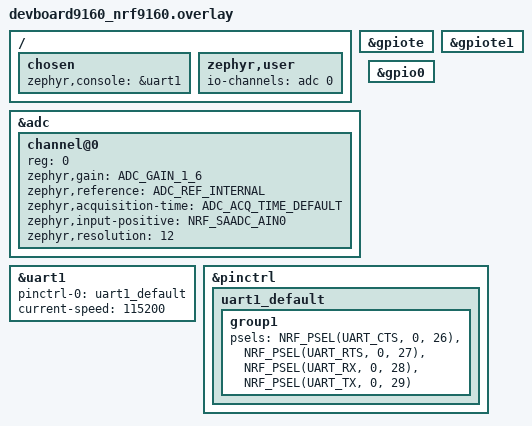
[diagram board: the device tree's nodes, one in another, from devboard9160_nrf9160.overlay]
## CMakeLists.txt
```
# SPDX-License-Identifier: Apache-2.0

cmake_minimum_required(VERSION 3.20.0)

find_package(Zephyr REQUIRED HINTS $ENV{ZEPHYR_BASE})
project(adc_simple)

target_sources(app PRIVATE src/main.c)
```

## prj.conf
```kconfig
CONFIG_GPIO=y

##enable the console
CONFIG_CONSOLE=y
CONFIG_UART_CONSOLE=y
CONFIG_SERIAL=y


#enable the logs
CONFIG_LOG=y
CONFIG_LOG_INFO_COLOR_GREEN=y
CONFIG_LOG_DBG_COLOR_BLUE=y

#enable ADC module
CONFIG_ADC=y
```

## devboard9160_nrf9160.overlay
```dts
/ {
	chosen {
		zephyr,console = &uart1;
	};

	zephyr,user {
		io-channels = <&adc 0>;
	};
};

&gpiote {
	status = "okay";
};

&gpiote1 {
	status = "okay";
};

&adc {
	#address-cells = <1>;
	#size-cells = <0>;
	status = "okay";
	channel@0 {
		reg = <0>;
		zephyr,gain = "ADC_GAIN_1_6";
		zephyr,reference = "ADC_REF_INTERNAL";
        zephyr,acquisition-time = <ADC_ACQ_TIME_DEFAULT>;
        zephyr,input-positive = <NRF_SAADC_AIN0>;
		zephyr,resolution = <12>;
	};
};

&gpio0 {
	status = "okay";
};

&uart1 {
	status = "okay";
	pinctrl-0 = <&uart1_default>;
	pinctrl-names = "default";
	current-speed = <115200>;
};

&pinctrl {
	uart1_default: uart1_default {
		group1 {
			psels = <NRF_PSEL(UART_CTS, 0, 26)>,
					<NRF_PSEL(UART_RTS, 0, 27)>,
					<NRF_PSEL(UART_RX, 0, 28)>,
					<NRF_PSEL(UART_TX, 0, 29)>;
		};
	};
};
```

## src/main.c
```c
/**
 * @file main.c
 * @author Ankit Bansal (iotdevelope@gmail.com)
 * @brief 
 * @version 0.1
 * @date 2025-01-24
 * 
 * @copyright Copyright (c) 2025
 * 
 */

/******************************************************************************
 * INCLUDES
 ******************************************************************************/
#include <stdio.h>
#include <zephyr/devicetree.h>
#include <zephyr/logging/log.h>
#include <zephyr/drivers/adc.h>

/******************************************************************************
 * EXTERN VARIABLES
 ******************************************************************************/

/******************************************************************************
 * PRIVATE MACROS AND DEFINES
 ******************************************************************************/
LOG_MODULE_REGISTER(main);
/******************************************************************************
 * PRIVATE TYPEDEFS
 ******************************************************************************/

/******************************************************************************
 * STATIC VARIABLES
 ******************************************************************************/
static const struct adc_dt_spec adc_channel = ADC_DT_SPEC_GET(DT_PATH(zephyr_user));

/******************************************************************************
 * GLOBAL VARIABLES
 ******************************************************************************/

/******************************************************************************
 * STATIC FUNCTION PROTOTYPES
 ******************************************************************************/

/******************************************************************************
 * STATIC FUNCTIONS
 ******************************************************************************/

/******************************************************************************
 * GLOBAL FUNCTIONS
 ******************************************************************************/


/******************************************************************************
* Function Prototypes
*******************************************************************************/

/******************************************************************************
* Function Definitions
*******************************************************************************/

int main()
{
    int err;
    if (!adc_is_ready_dt(&adc_channel))
    {
        LOG_ERR("ADC controller devivce %s not ready", adc_channel.dev->name);
        return 0;
    }

    err = adc_channel_setup_dt(&adc_channel);
    if( err < 0 )
    {
        LOG_ERR("Could not setup channel #%d (%d)", 0, err);
        return 0;
    }

    int16_t buf;
    struct adc_sequence sequence = {
        .buffer = &buf,
        .buffer_size = sizeof(buf),
    };

    err = adc_sequence_init_dt(&adc_channel, &sequence);
	if (err < 0) {
		LOG_ERR("Could not initalize sequnce");
		return 0;
	}

    int adc_mv;
    while (1)    
    {
        err = adc_read_dt(&adc_channel, &sequence);
        if (err < 0)
        {
            LOG_ERR("Could not read from sequnce %d", err);
            return 0;
        }
        adc_mv = (int)buf;
        LOG_INF("ADC raw value reading: %d", adc_mv);

        err = adc_raw_to_millivolts_dt(&adc_channel, &adc_mv);
        if (err < 0)
        {
            LOG_ERR("Could not convert raw value to millivolts %d", err);
            return 0;
        }
        LOG_INF("ADC millivolts reading: %d", adc_mv);

        k_sleep(K_MSEC(1000));
    }

    return 0;
}
```
